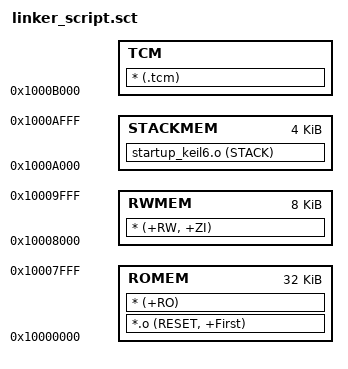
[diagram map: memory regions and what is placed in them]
;******************************************************************************
;
; Scatter file for Keil linker configuration.
;
;******************************************************************************
LR_1 0x10000000
{
    ROMEM 0x10000000 0x00008000
    {
        *.o (RESET, +First)
        * (+RO)
    }

    RWMEM 0x10008000 0x00002000
    {
        * (+RW, +ZI)
    }

    TCM 0x1000B000 0x00000000
    {
        * (.tcm)
    }

    STACKMEM 0x1000A000 0x00001000
    {
        startup_keil6.o (STACK)
    }
}
